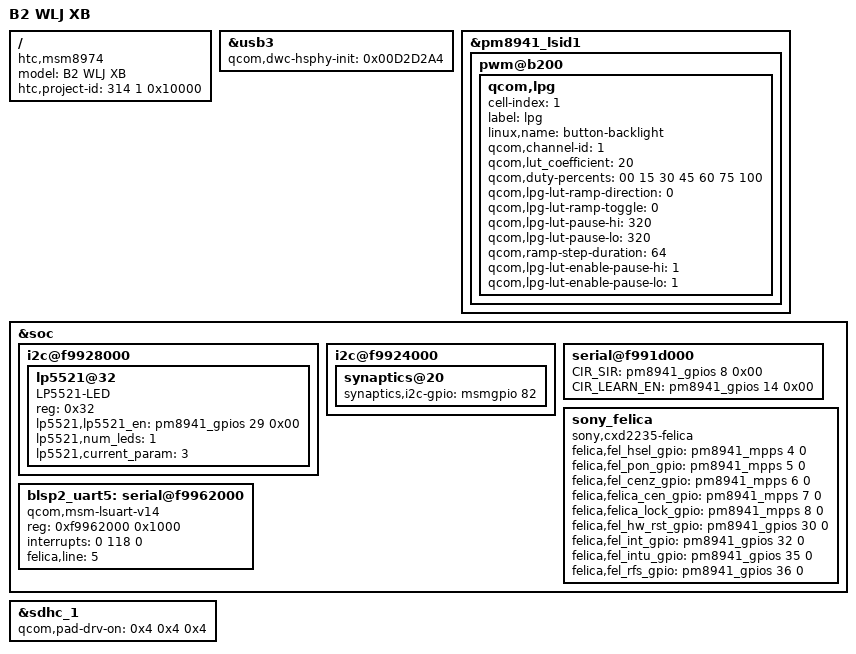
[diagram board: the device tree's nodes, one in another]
/* Copyright (c) 2013, The Linux Foundation. All rights reserved.
 *
 * This program is free software; you can redistribute it and/or modify
 * it under the terms of the GNU General Public License version 2 and
 * only version 2 as published by the Free Software Foundation.
 *
 * This program is distributed in the hope that it will be useful,
 * but WITHOUT ANY WARRANTY; without even the implied warranty of
 * MERCHANTABILITY or FITNESS FOR A PARTICULAR PURPOSE.  See the
 * GNU General Public License for more details.
 */

/dts-v1/;

/include/ "msm8974pro-ab-pm8941.dtsi"
/include/ "msm8974-b2-common.dtsi"
/include/ "msm8974-camera-sensor-b2-ver-b.dtsi"
/include/ "msm8974-b2wlj-pmicgpio.dtsi"
/include/ "msm8974-touch-b2-config.dtsi"
/include/ "msm8974-b2-storage.dtsi"

/ {
	model = "B2 WLJ XB";
	compatible = "htc,msm8974", "htc,b2wlj", "qcom,msm8974-mtp", "qcom,msm8974", "qcom,mtp";
	htc,project-id = <314 1 0x10000>;
};

&usb3 {
		qcom,dwc-hsphy-init = <0x00D2D2A4>;
};

&pm8941_lsid1 {
	pwm@b200 {
		qcom,lpg {
			cell-index = <1>;
			label = "lpg";
			linux,name = "button-backlight";
			qcom,channel-id = <1>;
			qcom,lut_coefficient = <20>;
			qcom,duty-percents = <00 15 30 45 60 75 100>; //Use percents in decimal, not in hex like in LED duty-pcts array
			qcom,lpg-lut-ramp-direction = <0>;
			qcom,lpg-lut-ramp-toggle = <0>;
			qcom,lpg-lut-pause-hi = <320>;
			qcom,lpg-lut-pause-lo = <320>;
			qcom,ramp-step-duration = <64>;
			qcom,lpg-lut-enable-pause-hi = <1>;
			qcom,lpg-lut-enable-pause-lo = <1>;
		};
	};
};

&soc {
	i2c@f9928000 {
		lp5521@32 {
			compatible = "LP5521-LED";
			reg = <0x32>;
			lp5521,lp5521_en = <&pm8941_gpios 29 0x00>;
			lp5521,num_leds = <1>;
			lp5521,current_param = <3>;
		};
	};

	i2c@f9924000 {
		synaptics@20 {
			synaptics,i2c-gpio = <&msmgpio 82 0x00>;
		};
	};

	serial@f991d000 {
		CIR_SIR = <&pm8941_gpios 8 0x00>;
		CIR_LEARN_EN = <&pm8941_gpios 14 0x00>;
	};
};

&sdhc_1 {
	qcom,pad-drv-on = <0x4 0x4 0x4>; /* 10mA, 10mA, 10mA */
};

/* FeliCa Start */
&soc {
	sony_felica {
		compatible   = "sony,cxd2235-felica";
		felica,fel_hsel_gpio = <&pm8941_mpps 4 0>;
		felica,fel_pon_gpio = <&pm8941_mpps 5 0>;
		felica,fel_cenz_gpio = <&pm8941_mpps 6 0>;
		felica,felica_cen_gpio = <&pm8941_mpps 7 0>;
		felica,felica_lock_gpio = <&pm8941_mpps 8 0>;
		felica,fel_hw_rst_gpio  = <&pm8941_gpios 30 0>;
		felica,fel_int_gpio  = <&pm8941_gpios 32 0>;
		felica,fel_intu_gpio  = <&pm8941_gpios 35 0>;
		felica,fel_rfs_gpio  = <&pm8941_gpios 36 0>;
	};
	blsp2_uart5: serial@f9962000 {
		compatible = "qcom,msm-lsuart-v14";
		reg = <0xf9962000 0x1000>;
		interrupts = <0 118 0>;
		felica,line = <5>;
		status = "ok";
	};
};
/* FeliCa End */
